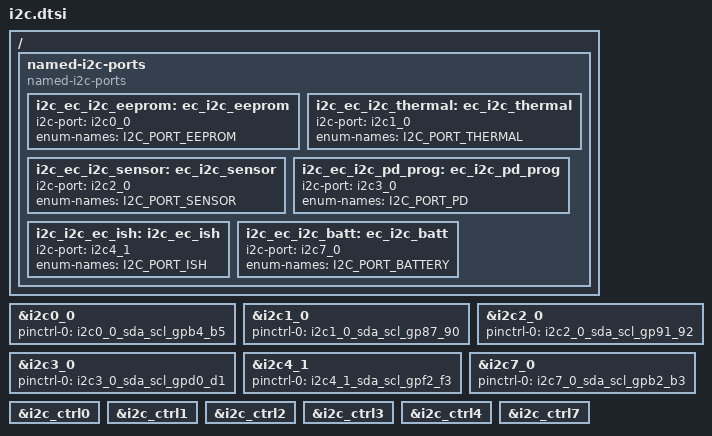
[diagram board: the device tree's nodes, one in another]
/* Copyright 2024 The ChromiumOS Authors
 * Use of this source code is governed by a BSD-style license that can be
 * found in the LICENSE file.
 */

/ {
	named-i2c-ports {
		compatible = "named-i2c-ports";

		i2c_ec_i2c_eeprom: ec_i2c_eeprom {
			i2c-port = <&i2c0_0>;
			enum-names = "I2C_PORT_EEPROM";
		};
		i2c_ec_i2c_thermal: ec_i2c_thermal {
			i2c-port = <&i2c1_0>;
			enum-names = "I2C_PORT_THERMAL";
		};
		i2c_ec_i2c_sensor: ec_i2c_sensor {
			i2c-port = <&i2c2_0>;
			enum-names = "I2C_PORT_SENSOR";
		};
		i2c_ec_i2c_pd_prog: ec_i2c_pd_prog {
			i2c-port = <&i2c3_0>;
			enum-names = "I2C_PORT_PD";
		};
		i2c_i2c_ec_ish: i2c_ec_ish {
			i2c-port = <&i2c4_1>;
			enum-names = "I2C_PORT_ISH";
		};
		i2c_ec_i2c_batt: ec_i2c_batt {
			i2c-port = <&i2c7_0>;
			enum-names = "I2C_PORT_BATTERY";
		};
	};
};

&i2c0_0 {
	status = "okay";
	pinctrl-0 = <&i2c0_0_sda_scl_gpb4_b5>;
	pinctrl-names = "default";
};

&i2c1_0 {
	status = "okay";
	pinctrl-0 = <&i2c1_0_sda_scl_gp87_90>;
	pinctrl-names = "default";
};

&i2c2_0 {
	status = "okay";
	pinctrl-0 = <&i2c2_0_sda_scl_gp91_92>;
	pinctrl-names = "default";
};

&i2c3_0 {
	status = "okay";
	pinctrl-0 = <&i2c3_0_sda_scl_gpd0_d1>;
	pinctrl-names = "default";
};

&i2c4_1 {
	status = "okay";
	pinctrl-0 = <&i2c4_1_sda_scl_gpf2_f3>;
	pinctrl-names = "default";
};

&i2c7_0 {
	status = "okay";
	pinctrl-0 = <&i2c7_0_sda_scl_gpb2_b3>;
	pinctrl-names = "default";
};

&i2c_ctrl0 {
	status = "okay";
};

&i2c_ctrl1 {
	status = "okay";
};

&i2c_ctrl2 {
	status = "okay";
};

&i2c_ctrl3 {
	status = "okay";
};

&i2c_ctrl4 {
	status = "okay";
};

&i2c_ctrl7 {
	status = "okay";
};
